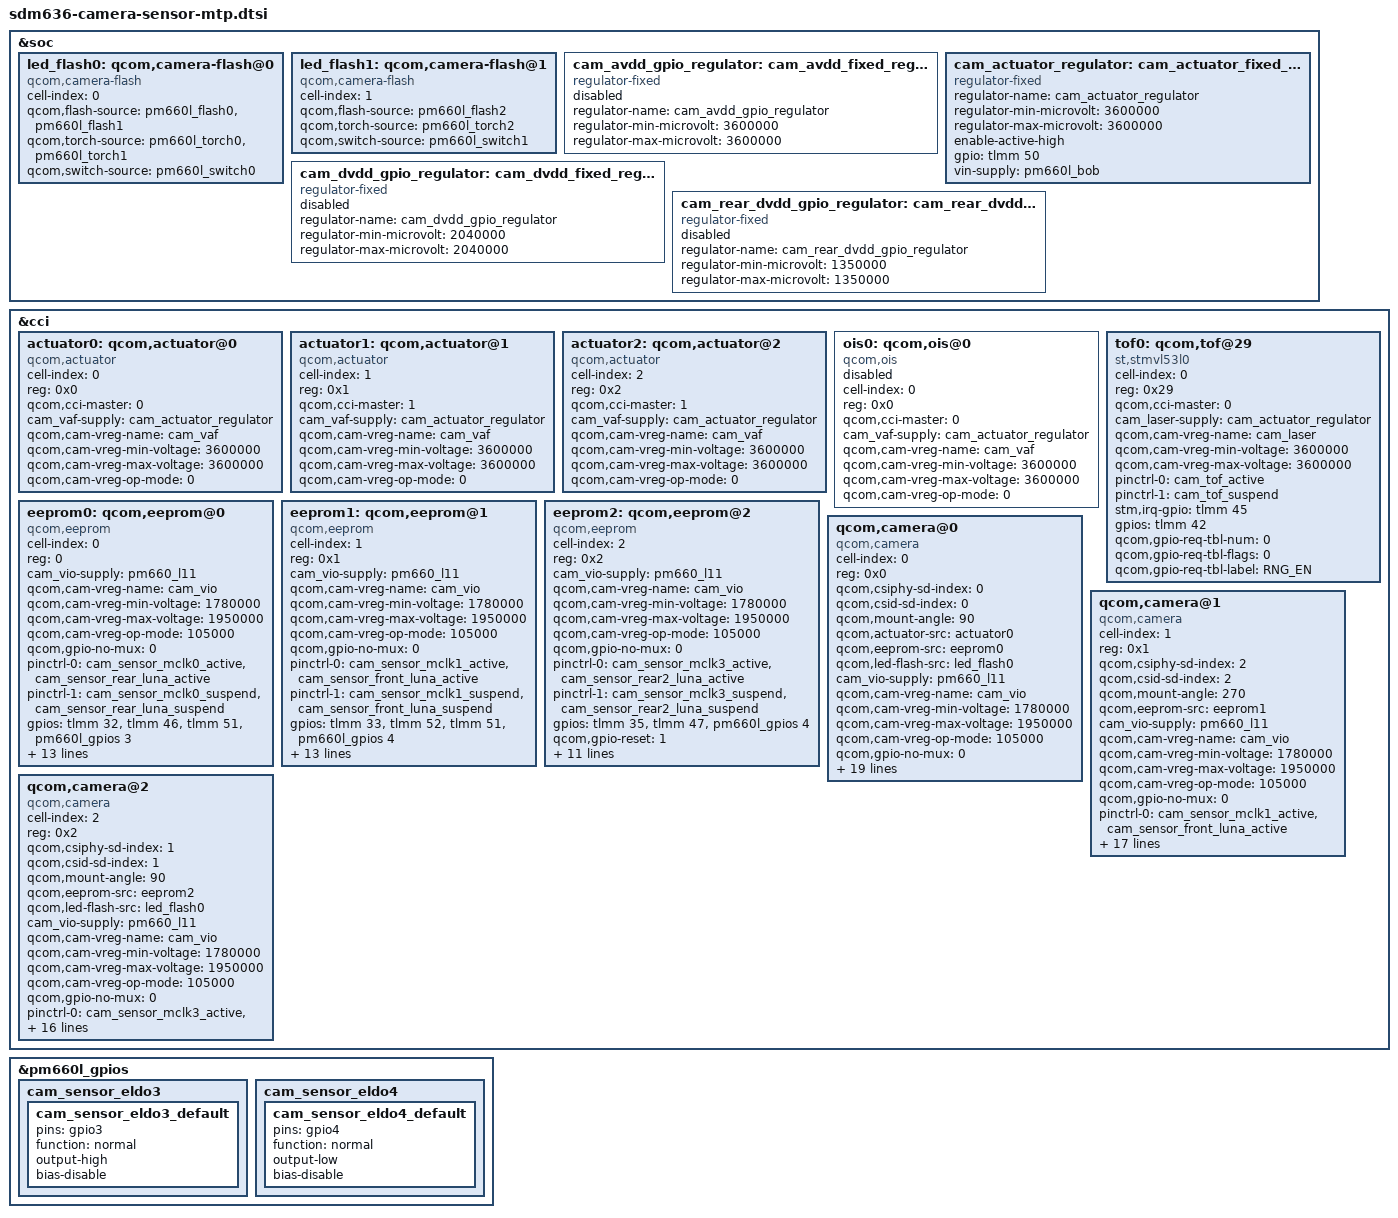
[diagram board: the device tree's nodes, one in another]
/*
 * Copyright (c) 2017, The Linux Foundation. All rights reserved.
 *
 * This program is free software; you can redistribute it and/or modify
 * it under the terms of the GNU General Public License version 2 and
 * only version 2 as published by the Free Software Foundation.
 *
 * This program is distributed in the hope that it will be useful,
 * but WITHOUT ANY WARRANTY; without even the implied warranty of
 * MERCHANTABILITY or FITNESS FOR A PARTICULAR PURPOSE.  See the
 * GNU General Public License for more details.
 */

&soc {
	led_flash0: qcom,camera-flash@0 {
		cell-index = <0>;
		compatible = "qcom,camera-flash";
		qcom,flash-source = <&pm660l_flash0 &pm660l_flash1>;
		qcom,torch-source = <&pm660l_torch0 &pm660l_torch1>;
		qcom,switch-source = <&pm660l_switch0>;
		status = "ok";
	};

	led_flash1: qcom,camera-flash@1 {
		cell-index = <1>;
		compatible = "qcom,camera-flash";
		qcom,flash-source = <&pm660l_flash2>;
		qcom,torch-source = <&pm660l_torch2>;
		qcom,switch-source = <&pm660l_switch1>;
		status = "ok";
	};

	/* KEY2 LE (luna): camera blobs control VANA/VDIG directly through
	 * GPIOs. Disable the overlapping fixed regulators to avoid GPIO
	 * conflicts, but retain the dedicated actuator regulator. */
	cam_avdd_gpio_regulator: cam_avdd_fixed_regulator {
		compatible = "regulator-fixed";
		regulator-name = "cam_avdd_gpio_regulator";
		regulator-min-microvolt = <3600000>;
		regulator-max-microvolt = <3600000>;
		status = "disabled";
	};

	cam_actuator_regulator: cam_actuator_fixed_regulator {
		compatible = "regulator-fixed";
		regulator-name = "cam_actuator_regulator";
		regulator-min-microvolt = <3600000>;
		regulator-max-microvolt = <3600000>;
		enable-active-high;
		gpio = <&tlmm 50 0>;
		vin-supply = <&pm660l_bob>;
	};

	cam_dvdd_gpio_regulator: cam_dvdd_fixed_regulator {
		compatible = "regulator-fixed";
		regulator-name = "cam_dvdd_gpio_regulator";
		regulator-min-microvolt = <2040000>;
		regulator-max-microvolt = <2040000>;
		status = "disabled";
	};

	cam_rear_dvdd_gpio_regulator: cam_rear_dvdd_fixed_regulator {
		compatible = "regulator-fixed";
		regulator-name = "cam_rear_dvdd_gpio_regulator";
		regulator-min-microvolt = <1350000>;
		regulator-max-microvolt = <1350000>;
		status = "disabled";
	};
};

&cci {
	actuator0: qcom,actuator@0 {
		cell-index = <0>;
		reg = <0x0>;
		compatible = "qcom,actuator";
		qcom,cci-master = <0>;
		cam_vaf-supply = <&cam_actuator_regulator>;
		qcom,cam-vreg-name = "cam_vaf";
		qcom,cam-vreg-min-voltage = <3600000>;
		qcom,cam-vreg-max-voltage = <3600000>;
		qcom,cam-vreg-op-mode = <0>;
	};

	actuator1: qcom,actuator@1 {
		cell-index = <1>;
		reg = <0x1>;
		compatible = "qcom,actuator";
		qcom,cci-master = <1>;
		cam_vaf-supply = <&cam_actuator_regulator>;
		qcom,cam-vreg-name = "cam_vaf";
		qcom,cam-vreg-min-voltage = <3600000>;
		qcom,cam-vreg-max-voltage = <3600000>;
		qcom,cam-vreg-op-mode = <0>;
	};

	actuator2: qcom,actuator@2 {
		cell-index = <2>;
		reg = <0x2>;
		compatible = "qcom,actuator";
		qcom,cci-master = <1>;
		cam_vaf-supply = <&cam_actuator_regulator>;
		qcom,cam-vreg-name = "cam_vaf";
		qcom,cam-vreg-min-voltage = <3600000>;
		qcom,cam-vreg-max-voltage = <3600000>;
		qcom,cam-vreg-op-mode = <0>;
	};

	ois0: qcom,ois@0 {
		cell-index = <0>;
		reg = <0x0>;
		compatible = "qcom,ois";
		qcom,cci-master = <0>;
		cam_vaf-supply = <&cam_actuator_regulator>;
		qcom,cam-vreg-name = "cam_vaf";
		qcom,cam-vreg-min-voltage = <3600000>;
		qcom,cam-vreg-max-voltage = <3600000>;
		qcom,cam-vreg-op-mode = <0>;
		status = "disabled";
	};

	tof0: qcom,tof@29 {
		cell-index = <0>;
		reg = <0x29>;
		compatible = "st,stmvl53l0";
		qcom,cci-master = <0>;
		cam_laser-supply = <&cam_actuator_regulator>;
		qcom,cam-vreg-name =  "cam_laser";
		qcom,cam-vreg-min-voltage = <3600000>;
		qcom,cam-vreg-max-voltage = <3600000>;
		pinctrl-names = "cam_default", "cam_suspend";
		pinctrl-0 = <&cam_tof_active>;
		pinctrl-1 = <&cam_tof_suspend>;
		stm,irq-gpio = <&tlmm 45  0x2008>;
		gpios = <&tlmm 42 0>;
		qcom,gpio-req-tbl-num = <0>;
		qcom,gpio-req-tbl-flags = <0>;
		qcom,gpio-req-tbl-label = "RNG_EN";
	};

	/* eeprom0: rear main - match luna 4.4 DT */
	eeprom0: qcom,eeprom@0 {
		cell-index = <0>;
		reg = <0>;
		compatible = "qcom,eeprom";
		cam_vio-supply = <&pm660_l11>;
		qcom,cam-vreg-name = "cam_vio";
		qcom,cam-vreg-min-voltage = <1780000>;
		qcom,cam-vreg-max-voltage = <1950000>;
		qcom,cam-vreg-op-mode = <105000>;
		qcom,gpio-no-mux = <0>;
		pinctrl-names = "cam_default", "cam_suspend";
		pinctrl-0 = <&cam_sensor_mclk0_active
				 &cam_sensor_rear_luna_active>;
		pinctrl-1 = <&cam_sensor_mclk0_suspend
				 &cam_sensor_rear_luna_suspend>;
		gpios = <&tlmm 32 0>,
			<&tlmm 46 0>,
			<&tlmm 51 0>,
			<&pm660l_gpios 3 0>;
		qcom,gpio-reset = <1>;
		qcom,gpio-vana = <2>;
		qcom,gpio-vdig = <3>;
		qcom,gpio-req-tbl-num = <0 1 2 3>;
		qcom,gpio-req-tbl-flags = <1 0 0 0 >;
		qcom,gpio-req-tbl-label = "CAMIF_MCLK0",
					"CAM_RESET0",
					"CAM_VANA0",
					"CAM_VDIG0";
		qcom,sensor-position = <0>;
		qcom,sensor-mode = <0>;
		qcom,cci-master = <0>;
		status = "ok";
		clocks = <&clock_mmss MCLK0_CLK_SRC>,
				<&clock_mmss MMSS_CAMSS_MCLK0_CLK>;
		clock-names = "cam_src_clk", "cam_clk";
		qcom,clock-rates = <24000000 0>;
	};

	/* eeprom1: front camera - match luna 4.4 DT */
	eeprom1: qcom,eeprom@1 {
		cell-index = <1>;
		reg = <0x1>;
		compatible = "qcom,eeprom";
		cam_vio-supply = <&pm660_l11>;
		qcom,cam-vreg-name = "cam_vio";
		qcom,cam-vreg-min-voltage = <1780000>;
		qcom,cam-vreg-max-voltage = <1950000>;
		qcom,cam-vreg-op-mode = <105000>;
		qcom,gpio-no-mux = <0>;
		pinctrl-names = "cam_default", "cam_suspend";
		pinctrl-0 = <&cam_sensor_mclk1_active
				 &cam_sensor_front_luna_active>;
		pinctrl-1 = <&cam_sensor_mclk1_suspend
				 &cam_sensor_front_luna_suspend>;
		gpios = <&tlmm 33 0>,
			<&tlmm 52 0>,
			<&tlmm 51 0>,
			<&pm660l_gpios 4 0>;
		qcom,gpio-reset = <1>;
		qcom,gpio-vana = <2>;
		qcom,gpio-vdig = <3>;
		qcom,gpio-req-tbl-num = <0 1 2 3>;
		qcom,gpio-req-tbl-flags = <1 0 0 0>;
		qcom,gpio-req-tbl-label = "CAMIF_MCLK1",
					"CAM_RESET1",
					"CAM_VANA1",
					"CAM_VDIG1";
		qcom,sensor-position = <0>;
		qcom,sensor-mode = <0>;
		qcom,cci-master = <1>;
		status = "ok";
		clocks = <&clock_mmss MCLK1_CLK_SRC>,
			<&clock_mmss MMSS_CAMSS_MCLK1_CLK>;
		clock-names = "cam_src_clk", "cam_clk";
		qcom,clock-rates = <24000000 0>;
	};

	/* eeprom2: third camera - match luna 4.4 DT */
	eeprom2: qcom,eeprom@2 {
		cell-index = <2>;
		reg = <0x2>;
		compatible = "qcom,eeprom";
		cam_vio-supply = <&pm660_l11>;
		qcom,cam-vreg-name = "cam_vio";
		qcom,cam-vreg-min-voltage = <1780000>;
		qcom,cam-vreg-max-voltage = <1950000>;
		qcom,cam-vreg-op-mode = <105000>;
		qcom,gpio-no-mux = <0>;
		pinctrl-names = "cam_default", "cam_suspend";
		pinctrl-0 = <&cam_sensor_mclk3_active
				 &cam_sensor_rear2_luna_active>;
		pinctrl-1 = <&cam_sensor_mclk3_suspend
				 &cam_sensor_rear2_luna_suspend>;
		gpios = <&tlmm 35 0>,
			<&tlmm 47 0>,
			<&pm660l_gpios 4 0>;
		qcom,gpio-reset = <1>;
		qcom,gpio-vana = <2>;
		qcom,gpio-req-tbl-num = <0 1 2>;
		qcom,gpio-req-tbl-flags = <1 0 0>;
		qcom,gpio-req-tbl-label = "CAMIF_MCLK3",
					"CAM_RESET2",
					"CAM_VANA2";
		qcom,sensor-position = <0>;
		qcom,sensor-mode = <0>;
		qcom,cci-master = <1>;
		status = "ok";
		clocks = <&clock_mmss MCLK3_CLK_SRC>,
			<&clock_mmss MMSS_CAMSS_MCLK3_CLK>;
		clock-names = "cam_src_clk", "cam_clk";
		qcom,clock-rates = <24000000 0>;
	};

	/* camera@0: rear main - match luna 4.4 DT */
	qcom,camera@0 {
		cell-index = <0>;
		compatible = "qcom,camera";
		reg = <0x0>;
		qcom,csiphy-sd-index = <0>;
		qcom,csid-sd-index = <0>;
		qcom,mount-angle = <90>;
		qcom,actuator-src = <&actuator0>;
		qcom,eeprom-src = <&eeprom0>;
		qcom,led-flash-src = <&led_flash0>;
		cam_vio-supply = <&pm660_l11>;
		qcom,cam-vreg-name = "cam_vio";
		qcom,cam-vreg-min-voltage = <1780000>;
		qcom,cam-vreg-max-voltage = <1950000>;
		qcom,cam-vreg-op-mode = <105000>;
		qcom,gpio-no-mux = <0>;
		pinctrl-names = "cam_default", "cam_suspend";
		pinctrl-0 = <&cam_sensor_mclk0_active
				 &cam_sensor_rear_luna_active>;
		pinctrl-1 = <&cam_sensor_mclk0_suspend
				 &cam_sensor_rear_luna_suspend>;
		gpios = <&tlmm 32 0>,
			<&tlmm 46 0>,
			<&tlmm 51 0>,
			<&pm660l_gpios 3 0>;
		qcom,gpio-reset = <1>;
		qcom,gpio-vana = <2>;
		qcom,gpio-vdig = <3>;
		qcom,gpio-req-tbl-num = <0 1 2 3>;
		qcom,gpio-req-tbl-flags = <1 0 0 0 >;
		qcom,gpio-req-tbl-label = "CAMIF_MCLK0",
					"CAM_RESET0",
					"CAM_VANA0",
					"CAM_VDIG0";
		qcom,sensor-position = <0>;
		qcom,sensor-mode = <0>;
		qcom,cci-master = <0>;
		status = "ok";
		clocks = <&clock_mmss MCLK0_CLK_SRC>,
				<&clock_mmss MMSS_CAMSS_MCLK0_CLK>;
		clock-names = "cam_src_clk", "cam_clk";
		qcom,clock-rates = <24000000 0>;
	};

	/* camera@1: front camera - match luna 4.4 DT */
	qcom,camera@1 {
		cell-index = <1>;
		compatible = "qcom,camera";
		reg = <0x1>;
		qcom,csiphy-sd-index = <2>;
		qcom,csid-sd-index = <2>;
		qcom,mount-angle = <270>;
		qcom,eeprom-src = <&eeprom1>;
		cam_vio-supply = <&pm660_l11>;
		qcom,cam-vreg-name = "cam_vio";
		qcom,cam-vreg-min-voltage = <1780000>;
		qcom,cam-vreg-max-voltage = <1950000>;
		qcom,cam-vreg-op-mode = <105000>;
		qcom,gpio-no-mux = <0>;
		pinctrl-names = "cam_default", "cam_suspend";
		pinctrl-0 = <&cam_sensor_mclk1_active
				 &cam_sensor_front_luna_active>;
		pinctrl-1 = <&cam_sensor_mclk1_suspend
				 &cam_sensor_front_luna_suspend>;
		gpios = <&tlmm 33 0>,
			<&tlmm 52 0>,
			<&tlmm 51 0>,
			<&pm660l_gpios 4 0>;
		qcom,gpio-reset = <1>;
		qcom,gpio-vana = <2>;
		qcom,gpio-vdig = <3>;
		qcom,gpio-req-tbl-num = <0 1 2 3>;
		qcom,gpio-req-tbl-flags = <1 0 0 0 >;
		qcom,gpio-req-tbl-label = "CAMIF_MCLK1",
					"CAM_RESET1",
					"CAM_VANA1",
					"CAM_VDIG1";
		qcom,sensor-position = <0>;
		qcom,sensor-mode = <0>;
		qcom,cci-master = <1>;
		status = "ok";
		clocks = <&clock_mmss MCLK1_CLK_SRC>,
			<&clock_mmss MMSS_CAMSS_MCLK1_CLK>;
		clock-names = "cam_src_clk", "cam_clk";
		qcom,clock-rates = <24000000 0>;
	};


	/* camera@2: third camera - match luna 4.4 DT */
	qcom,camera@2 {
		cell-index = <2>;
		compatible = "qcom,camera";
		reg = <0x2>;
		qcom,csiphy-sd-index = <1>;
		qcom,csid-sd-index = <1>;
		qcom,mount-angle = <90>;
		qcom,eeprom-src = <&eeprom2>;
		qcom,led-flash-src = <&led_flash0>;
		cam_vio-supply = <&pm660_l11>;
		qcom,cam-vreg-name = "cam_vio";
		qcom,cam-vreg-min-voltage = <1780000>;
		qcom,cam-vreg-max-voltage = <1950000>;
		qcom,cam-vreg-op-mode = <105000>;
		qcom,gpio-no-mux = <0>;
		pinctrl-names = "cam_default", "cam_suspend";
		pinctrl-0 = <&cam_sensor_mclk3_active
				 &cam_sensor_rear2_luna_active>;
		pinctrl-1 = <&cam_sensor_mclk3_suspend
				 &cam_sensor_rear2_luna_suspend>;
		gpios = <&tlmm 35 0>,
			<&tlmm 47 0>,
			<&pm660l_gpios 4 0>;
		qcom,gpio-reset = <1>;
		qcom,gpio-vana = <2>;
		qcom,gpio-req-tbl-num = <0 1 2>;
		qcom,gpio-req-tbl-flags = <1 0 0>;
		qcom,gpio-req-tbl-label = "CAMIF_MCLK3",
					"CAM_RESET2",
					"CAM_VANA2";
		qcom,sensor-position = <0>;
		qcom,sensor-mode = <0>;
		qcom,cci-master = <1>;
		status = "ok";
		clocks = <&clock_mmss MCLK3_CLK_SRC>,
			<&clock_mmss MMSS_CAMSS_MCLK3_CLK>;
		clock-names = "cam_src_clk", "cam_clk";
		qcom,clock-rates = <24000000 0>;

	};
};

&pm660l_gpios {
	cam_sensor_eldo3 {
		cam_sensor_eldo3_default: cam_sensor_eldo3_default {
			pins = "gpio3";
			function = "normal";
			output-high;
			bias-disable;
		};
	};

	cam_sensor_eldo4 {
		cam_sensor_eldo4_default: cam_sensor_eldo4_default {
			pins = "gpio4";
			function = "normal";
			output-low;
			bias-disable;
		};
	};
};
